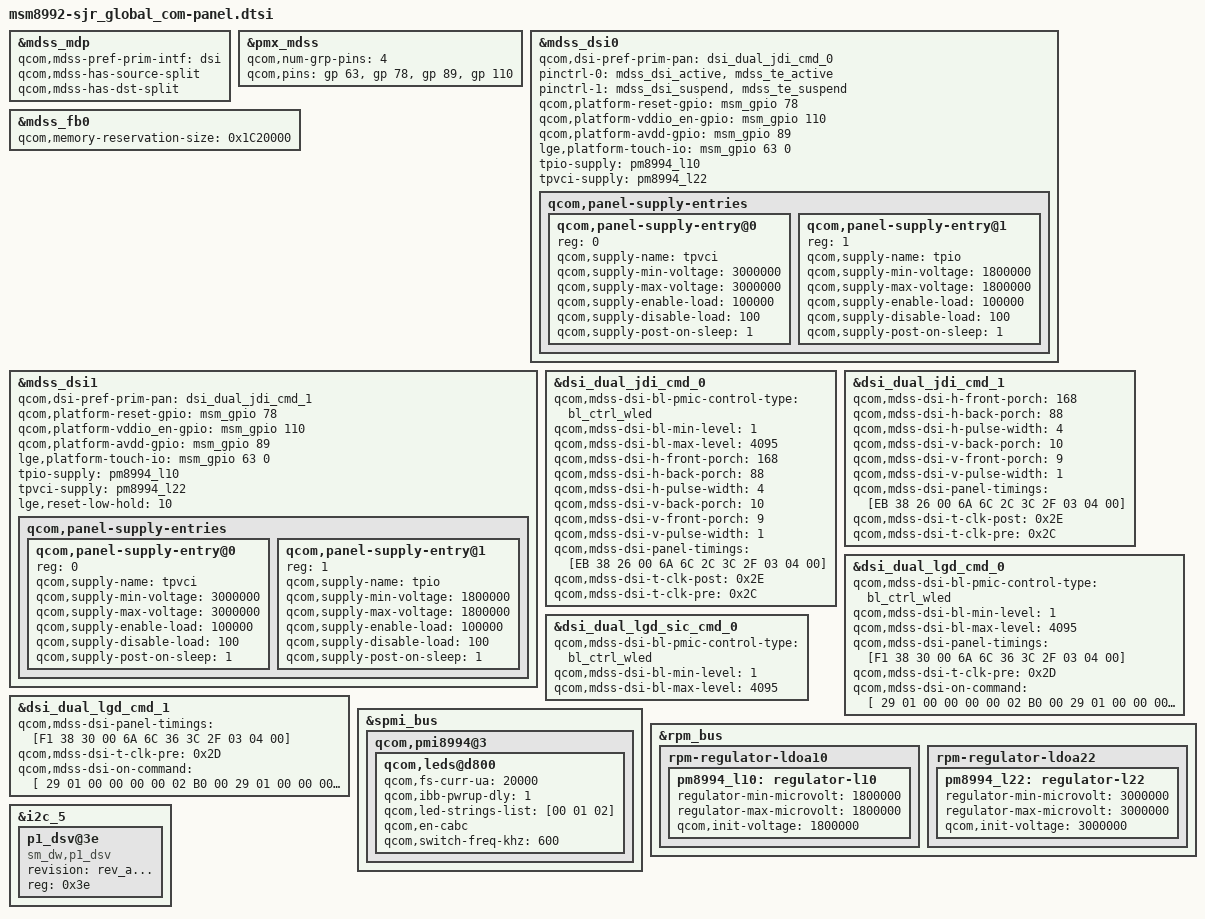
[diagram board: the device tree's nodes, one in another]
/* Copyright (c) 2014, The Linux Foundation. All rights reserved.
 *
 * This program is free software; you can redistribute it and/or modify
 * it under the terms of the GNU General Public License version 2 and
 * only version 2 as published by the Free Software Foundation.
 *
 * This program is distributed in the hope that it will be useful,
 * but WITHOUT ANY WARRANTY; without even the implied warranty of
 * MERCHANTABILITY or FITNESS FOR A PARTICULAR PURPOSE.  See the
 * GNU General Public License for more details.
 */

#include "../dsi-panel-jdi-nt36850-dualmipi0-qhd-cmd.dtsi"
#include "../dsi-panel-jdi-nt36850-dualmipi1-qhd-cmd.dtsi"
//#include "../dsi-panel-jdi-nt36850-dualmipi0-qhd-video.dtsi"
//#include "../dsi-panel-jdi-nt36850-dualmipi1-qhd-video.dtsi"
#include "../dsi-panel-lgd-r69007-dualmipi0-qhd-cmd.dtsi"
#include "../dsi-panel-lgd-r69007-dualmipi1-qhd-cmd.dtsi"
#include "../dsi-panel-lgd-lg4943-dualmipi0-qhd-cmd.dtsi"
#include "../dsi-panel-lgd-lg4943-dualmipi1-qhd-cmd.dtsi"

&mdss_mdp {
	qcom,mdss-pref-prim-intf = "dsi";
	qcom,mdss-has-source-split;
	qcom,mdss-has-dst-split;
	/delete-property/ qcom,mdss-ad-off;
};

&pmx_mdss {
	qcom,num-grp-pins = <4>;
	qcom,pins = <&gp 63>, <&gp 78>, <&gp 89>, <&gp 110>;
};


&mdss_dsi0 {
	qcom,dsi-pref-prim-pan = <&dsi_dual_jdi_cmd_0>;
	pinctrl-names = "mdss_default", "mdss_sleep";

	/* pinctrl-0 = <&mdss_dsi_active>; */
	/* pinctrl-1 = <&mdss_dsi_suspend>; */
	/* Add TE pin control status on the PINCTRL structure */
	pinctrl-0 = <&mdss_dsi_active &mdss_te_active>;
	pinctrl-1 = <&mdss_dsi_suspend &mdss_te_suspend>;

	qcom,platform-reset-gpio = <&msm_gpio 78 0>;
	/* qcom,dsi-panel-bias-vreg; */
	qcom,platform-vddio_en-gpio = <&msm_gpio 110 0>;
	qcom,platform-avdd-gpio = <&msm_gpio 89 0>;
	lge,platform-touch-io = <&msm_gpio 63 0>;


	tpio-supply = <&pm8994_l10>;
	tpvci-supply =  <&pm8994_l22>;

	qcom,panel-supply-entries {
		#address-cells = <1>;
		#size-cells = <0>;

		qcom,panel-supply-entry@0 {
			reg = <0>;
			qcom,supply-name = "tpvci";
			qcom,supply-min-voltage = <3000000>;
			qcom,supply-max-voltage = <3000000>;
			qcom,supply-enable-load = <100000>;
			qcom,supply-disable-load = <100>;
			qcom,supply-post-on-sleep = <1>;
		};

		qcom,panel-supply-entry@1 {
			reg = <1>;
			qcom,supply-name = "tpio";
			qcom,supply-min-voltage = <1800000>;
			qcom,supply-max-voltage = <1800000>;
			qcom,supply-enable-load = <100000>;
			qcom,supply-disable-load = <100>;
			qcom,supply-post-on-sleep = <1>;
		};
	};
};

&mdss_fb0 {
	qcom,memory-reservation-size = <0x1C20000>;
};

&mdss_dsi1 {
	qcom,dsi-pref-prim-pan = <&dsi_dual_jdi_cmd_1>;

	qcom,platform-reset-gpio = <&msm_gpio 78 0>;
	/* qcom,dsi-panel-bias-vreg; */
	qcom,platform-vddio_en-gpio = <&msm_gpio 110 0>;
	qcom,platform-avdd-gpio = <&msm_gpio 89 0>;
	lge,platform-touch-io = <&msm_gpio 63 0>;

	tpio-supply = <&pm8994_l10>;
	tpvci-supply =  <&pm8994_l22>;


	qcom,platform-reset-gpio = <&msm_gpio 78 0>;
	lge,reset-low-hold = <10>;
	qcom,platform-vddio_en-gpio = <&msm_gpio 110 0>;
	qcom,platform-avdd-gpio = <&msm_gpio 89 0>;

	qcom,panel-supply-entries {
		#address-cells = <1>;
		#size-cells = <0>;

		qcom,panel-supply-entry@0 {
			reg = <0>;
			qcom,supply-name = "tpvci";
			qcom,supply-min-voltage = <3000000>;
			qcom,supply-max-voltage = <3000000>;
			qcom,supply-enable-load = <100000>;
			qcom,supply-disable-load = <100>;
			qcom,supply-post-on-sleep = <1>;
		};

		qcom,panel-supply-entry@1 {
			reg = <1>;
			qcom,supply-name = "tpio";
			qcom,supply-min-voltage = <1800000>;
			qcom,supply-max-voltage = <1800000>;
			qcom,supply-enable-load = <100000>;
			qcom,supply-disable-load = <100>;
			qcom,supply-post-on-sleep = <1>;
		};
	};
};

&dsi_dual_jdi_cmd_0{
	qcom,mdss-dsi-bl-pmic-control-type = "bl_ctrl_wled";
	qcom,mdss-dsi-bl-min-level = <1>;
	qcom,mdss-dsi-bl-max-level = <4095>;
	qcom,mdss-dsi-h-front-porch = <168>;
	qcom,mdss-dsi-h-back-porch = <88>;
	qcom,mdss-dsi-h-pulse-width = <4>;
	qcom,mdss-dsi-v-back-porch = <10>;
	qcom,mdss-dsi-v-front-porch = <9>;
	qcom,mdss-dsi-v-pulse-width = <1>;
	qcom,mdss-dsi-panel-timings = [EB 38 26 00 6A 6C 2C 3C 2F 03 04 00];
	qcom,mdss-dsi-t-clk-post = <0x2E>;
	qcom,mdss-dsi-t-clk-pre = <0x2C>;
};

&dsi_dual_jdi_cmd_1{
	qcom,mdss-dsi-h-front-porch = <168>;
	qcom,mdss-dsi-h-back-porch = <88>;
	qcom,mdss-dsi-h-pulse-width = <4>;
	qcom,mdss-dsi-v-back-porch = <10>;
	qcom,mdss-dsi-v-front-porch = <9>;
	qcom,mdss-dsi-v-pulse-width = <1>;
	qcom,mdss-dsi-panel-timings = [EB 38 26 00 6A 6C 2C 3C 2F 03 04 00];
	qcom,mdss-dsi-t-clk-post = <0x2E>;
	qcom,mdss-dsi-t-clk-pre = <0x2C>;
};

&dsi_dual_lgd_cmd_0{
	qcom,mdss-dsi-bl-pmic-control-type = "bl_ctrl_wled";
	qcom,mdss-dsi-bl-min-level = <1>;
	qcom,mdss-dsi-bl-max-level = <4095>;
	qcom,mdss-dsi-panel-timings = [F1 38 30 00 6A 6C 36 3C 2F 03 04 00];
	qcom,mdss-dsi-t-clk-pre = <0x2D>;
	qcom,mdss-dsi-on-command = [
			/* Manufacturer Command Protection */
			29 01 00 00 00 00 02
			B0 00
			/* Interface Control */
			29 01 00 00 00 00 04
			B3 04 00 00
			/* DSI Control */
			29 01 00 00 00 00 04
			B6 3B D3 00
			/* Display Setting 1 */
			29 01 00 00 00 00 28
			C1 80 08 11 1F FC
			F2 C9 1F 5F 98
			B3 FE FF F7 FE
			FF D7 31 F1 CB
			3F 3F FD EF 03
			24 69 18 AA 40
			01 42 02 08 00
			01 00 01 00
			/* Display Setting 2 */
			29 01 00 00 00 00 0F
			C2 01 FA 00 04 64
			08 00 60 00 38
			70 00 00 00
			/* Display Setting 3 Active - V */
			29 01 00 00 00 00 09
			C3 07 01 08 01 00
			00 00 00
			/* Source Timing Setting & Sout Equalize Setting */
			29 01 00 00 00 00 12
			C4 70 00 00 00 02
			00 00 00 00 02
			01 00 01 01 00
			00 00
			/* LTPS Timing Setting */
			29 01 00 00 00 00 11
			C6 3C 00 3C 02 37
			01 0E 01 02 01
			02 03 0F 04 3C
			46
			/* Gamma Setting Common Set */
			29 01 00 00 00 00 1F
			C7 00 16 22 2C 3B
			48 51 5D 40 47
			53 61 6A 71 78
			00 16 22 2C 3B
			48 51 5D 40 47
			53 61 6A 71 78
			/* Digital Gamma Setting 1 */
			29 01 00 00 00 00 14
			C8 00 00 00 00 00
			FC 00 00 00 00
			00 FC 00 00 00
			00 00 FC 00
			/* Digital Gamma Setting 2 */
			29 01 00 00 00 00 14
			C9 00 00 00 00 00
			FC 00 00 00 00
			00 FC 00 00 00
			00 00 FC 00
			/* Panel PIN Control */
			29 01 00 00 00 00 14
			CB AA 1E E3 55 F1
			FF 00 00 00 00
			00 00 00 00 00
			00 00 00 00
			/* Panel IF Control */
			29 01 00 00 00 00 02
			CC 07
			/* V Black Control */
			29 01 00 00 00 00 0B
			CD 3A 86 3A 86 8D
			8D 04 04 00 00
			/* Power Setting(for CHGP) */
			29 01 00 00 00 00 11
			D0 99 01 91 68 A6
			59 19 00 00 00
			19 99 04 00 00
			00
			/* Power Setting for Internal Power */
			29 01 00 00 00 00 21
			D3 1B 3B BB 77 77
			77 BB B3 33 00
			80 A7 A0 5B 5B
			33 33 33 C0 00
			F2 0F 7D 7C FF
			0F 99 00 33 00
			FF FF
			/* Driving Option and Touch Setting */
			29 01 00 00 00 00 06
			D4 57 33 05 00 FF
			/* Vcom Setting */
			29 01 00 00 00 00 0C
			D5 66 00 00 01 3D
			01 3D 00 38 00
			38
			/* Sequencer Timing Control for Pon */
			29 01 00 00 00 00 22
			D7 04 FF 23 15 75
			A4 C3 1F C3 1F
			D9 07 1C 1F 30
			8E 87 C7 E3 F1
			CC F0 1F F0 0D
			70 00 2A 00 7E
			1D 07 00
			/* Sequencer Test Control */
			29 01 00 00 00 00 02
			D6 01

			/* IE setting Start */
			/* Color Enhancement */
			29 01 00 00 00 00 2C
			CA 1D FC DC DC
			00 FD FD 00 FD
			00 D9 D9 02 E3
			00 00 00 FC 00
			00 00 00 00 00
			00 00 00 00 00
			00 00 00 00 00
			00 00 00 00 00
			00 00 00 00

			/* BACKLIGHT CONTROL */
			//0205_01, 10kHz
			29 01 00 00 00 00 1A
			CE 55 40 46 4E
			57 60 6A 75 81
			8E 9B AA B9 C8
			D8 E6 FF 0A 00
			04 04 42 04 69
			5A


			/* BACKLIGHT CONTROL */
			//CABC, CR15
			29 01 00 00 00 00 08
			B8 45 3D 1A 0F
			0A 50 50 //CABC
			29 01 00 00 00 00 08
			BA 01 33 78 64 00 FF
			FF // SRE

			/* SRE CONTROL */
			29 01 00 00 00 00 03
			BB 14 14
			29 01 00 00 00 00 03
			BC 37 32 // MIDDLE
			29 01 00 00 00 00 03
			BD 64 00 // STRONG

			/* CABC_SRE SETTING */
			39 01 00 00 00 00 02
			53 24
			39 01 00 00 00 00 02
			55 81 //h4b SRE, l2b CABC
			/* IE setting End */

			/* Sleep out & Display on set */
			/* Host display data transfer start(HS) */
			/* Display On */
			05 01 00 00 00 00 01 29
			/* Sleep out & wait 73ms*/
			05 01 00 00 49 00 01 11

			/* CABC dimming on */
			39 01 00 00 00 00 02
			53 2C
			39 01 00 00 00 00 02
			51 FF
			];
};

&dsi_dual_lgd_cmd_1{
	qcom,mdss-dsi-panel-timings = [F1 38 30 00 6A 6C 36 3C 2F 03 04 00];
	qcom,mdss-dsi-t-clk-pre = <0x2D>;
	qcom,mdss-dsi-on-command = [
			/* Manufacturer Command Protection */
			29 01 00 00 00 00 02
			B0 00
			/* Interface Control */
			29 01 00 00 00 00 04
			B3 04 00 00
			/* DSI Control */
			29 01 00 00 00 00 04
			B6 3B D3 00
			/* Display Setting 1 */
			29 01 00 00 00 00 28
			C1 80 08 11 1F FC
			F2 C9 1F 5F 98
			B3 FE FF F7 FE
			FF D7 31 F1 CB
			3F 3F FD EF 03
			24 69 18 AA 40
			01 42 02 08 00
			01 00 01 00
			/* Display Setting 2 */
			29 01 00 00 00 00 0F
			C2 01 FA 00 04 64
			08 00 60 00 38
			70 00 00 00
			/* Display Setting 3 Active - V */
			29 01 00 00 00 00 09
			C3 07 01 08 01 00
			00 00 00
			/* Source Timing Setting & Sout Equalize Setting */
			29 01 00 00 00 00 12
			C4 70 00 00 00 02
			00 00 00 00 02
			01 00 01 01 00
			00 00
			/* LTPS Timing Setting */
			29 01 00 00 00 00 11
			C6 3C 00 3C 02 37
			01 0E 01 02 01
			02 03 0F 04 3C
			46
			/* Gamma Setting Common Set */
			29 01 00 00 00 00 1F
			C7 00 16 22 2C 3B
			48 51 5D 40 47
			53 61 6A 71 78
			00 16 22 2C 3B
			48 51 5D 40 47
			53 61 6A 71 78
			/* Digital Gamma Setting 1 */
			29 01 00 00 00 00 14
			C8 00 00 00 00 00
			FC 00 00 00 00
			00 FC 00 00 00
			00 00 FC 00
			/* Digital Gamma Setting 2 */
			29 01 00 00 00 00 14
			C9 00 00 00 00 00
			FC 00 00 00 00
			00 FC 00 00 00
			00 00 FC 00
			/* Panel PIN Control */
			29 01 00 00 00 00 14
			CB AA 1E E3 55 F1
			FF 00 00 00 00
			00 00 00 00 00
			00 00 00 00
			/* Panel IF Control */
			29 01 00 00 00 00 02
			CC 07
			/* V Black Control */
			29 01 00 00 00 00 0B
			CD 3A 86 3A 86 8D
			8D 04 04 00 00
			/* Power Setting(for CHGP) */
			29 01 00 00 00 00 11
			D0 99 01 91 68 A6
			59 19 00 00 00
			19 99 04 00 00
			00
			/* Power Setting for Internal Power */
			29 01 00 00 00 00 21
			D3 1B 3B BB 77 77
			77 BB B3 33 00
			80 A7 A0 5B 5B
			33 33 33 C0 00
			F2 0F 7D 7C FF
			0F 99 00 33 00
			FF FF
			/* Driving Option and Touch Setting */
			29 01 00 00 00 00 06
			D4 57 33 05 00 FF
			/* Vcom Setting */
			29 01 00 00 00 00 0C
			D5 66 00 00 01 3D
			01 3D 00 38 00
			38
			/* Sequencer Timing Control for Pon */
			29 01 00 00 00 00 22
			D7 04 FF 23 15 75
			A4 C3 1F C3 1F
			D9 07 1C 1F 30
			8E 87 C7 E3 F1
			CC F0 1F F0 0D
			70 00 2A 00 7E
			1D 07 00
			/* Sequencer Test Control */
			29 01 00 00 00 00 02
			D6 01

			/* IE setting Start */
			/* Color Enhancement */
			29 01 00 00 00 00 2C
			CA 1D FC DC DC
			00 FD FD 00 FD
			00 D9 D9 02 E3
			00 00 00 FC 00
			00 00 00 00 00
			00 00 00 00 00
			00 00 00 00 00
			00 00 00 00 00
			00 00 00 00

			/* BACKLIGHT CONTROL */
			//0205_01, 10kHz
			29 01 00 00 00 00 1A
			CE 55 40 46 4E
			57 60 6A 75 81
			8E 9B AA B9 C8
			D8 E6 FF 0A 00
			04 04 42 04 69
			5A


			/* BACKLIGHT CONTROL */
			//CABC, CR15
			29 01 00 00 00 00 08
			B8 45 3D 1A 0F
			0A 50 50 //CABC
			29 01 00 00 00 00 08
			BA 01 33 78 64 00 FF
			FF // SRE

			/* SRE CONTROL */
			29 01 00 00 00 00 03
			BB 14 14
			29 01 00 00 00 00 03
			BC 37 32 // MIDDLE
			29 01 00 00 00 00 03
			BD 64 00 // STRONG

			/* CABC_SRE SETTING */
			39 01 00 00 00 00 02
			53 24
			39 01 00 00 00 00 02
			55 81 //h4b SRE, l2b CABC
			/* IE setting End */

			/* Sleep out & Display on set */
			/* Host display data transfer start(HS) */
			/* Display On */
			05 01 00 00 00 00 01 29
			/* Sleep out & wait 73ms*/
			05 01 00 00 49 00 01 11

			/* CABC dimming on */
			39 01 00 00 00 00 02
			53 2C
			39 01 00 00 00 00 02
			51 FF
			];
};

&dsi_dual_lgd_sic_cmd_0{
	qcom,mdss-dsi-bl-pmic-control-type = "bl_ctrl_wled";
	qcom,mdss-dsi-bl-min-level = <1>;
	qcom,mdss-dsi-bl-max-level = <4095>;
};

&spmi_bus {
	qcom,pmi8994@3 {
		qcom,leds@d800 {
			qcom,fs-curr-ua = <20000>;
			qcom,ibb-pwrup-dly = <1>;
			qcom,led-strings-list = [00 01 02];
			qcom,en-cabc;
			qcom,switch-freq-khz = <600>;
		};
	};
};

/* RPM controlled regulators: */

&rpm_bus {
	rpm-regulator-ldoa10 {
		status = "okay";
		pm8994_l10: regulator-l10 {
			regulator-min-microvolt = <1800000>;
			regulator-max-microvolt = <1800000>;
			qcom,init-voltage = <1800000>;
			status = "okay";
		};

	};

	rpm-regulator-ldoa22 {
		status = "okay";
		pm8994_l22: regulator-l22 {
			regulator-min-microvolt = <3000000>;
			regulator-max-microvolt = <3000000>;
			qcom,init-voltage = <3000000>;
			status = "okay";
		};
	};
};

&i2c_5 {
    p1_dsv@3e {
        status = "ok";
        revision = "rev_a...";
        compatible = "sm_dw,p1_dsv";
        reg = <0x3e>;
    };
};
